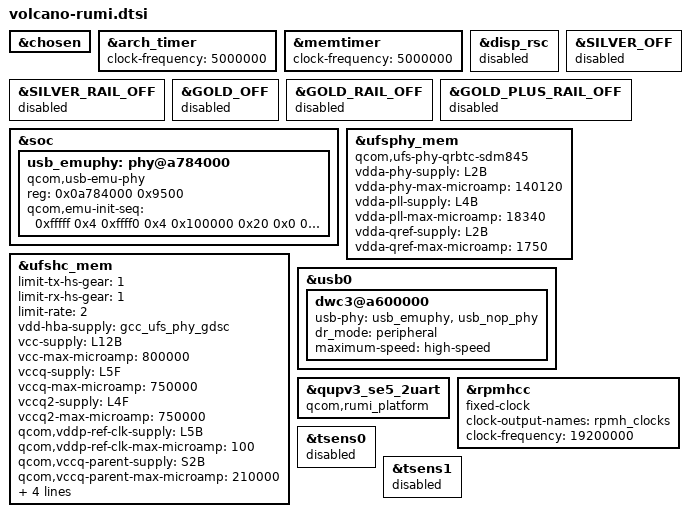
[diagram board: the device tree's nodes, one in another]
&chosen {
};

&arch_timer {
	clock-frequency = <5000000>;
};

&memtimer {
	clock-frequency = <5000000>;
};

&disp_rsc {
	status = "disabled";
};

&SILVER_OFF {
	status = "nok";
};

&SILVER_RAIL_OFF {
	status = "nok";
};

&GOLD_OFF {
	status = "nok";
};

&GOLD_RAIL_OFF {
	status = "nok";
};

&GOLD_PLUS_RAIL_OFF {
	status = "nok";
};

&soc {
	usb_emuphy: phy@a784000 {
		compatible = "qcom,usb-emu-phy";
		reg = <0x0a784000 0x9500>;

		qcom,emu-init-seq = <0xfffff 0x4
			0xffff0 0x4
			0x100000 0x20
			0x0 0x20
			0x000101F0 0x20
			0x00100000 0x3c
			0x0 0x3c
			0x0 0x4>;
	};
};

&ufsphy_mem {
	compatible = "qcom,ufs-phy-qrbtc-sdm845";

	/* VDDA_UFS_CORE */
	vdda-phy-supply = <&L2B>;
	vdda-phy-max-microamp = <140120>;

	/* VDDA_UFS_0_1P2 */
	vdda-pll-supply = <&L4B>;
	vdda-pll-max-microamp = <18340>;

	/* Qref power supply, Refer Qref diagram */
	vdda-qref-supply = <&L2B>;
	vdda-qref-max-microamp = <1750>;

	status = "ok";
};

&ufshc_mem {
	limit-tx-hs-gear = <1>;
	limit-rx-hs-gear = <1>;
	limit-rate = <2>; /* HS Rate-B */

	vdd-hba-supply = <&gcc_ufs_phy_gdsc>;

	vcc-supply = <&L12B>;
	vcc-max-microamp = <800000>;

	vccq-supply = <&L5F>;
	vccq-max-microamp = <750000>;

	vccq2-supply = <&L4F>;
	vccq2-max-microamp = <750000>;

	/* VDD_PX10 is voted for the ufs_reset_n */
	qcom,vddp-ref-clk-supply = <&L5B>;
	qcom,vddp-ref-clk-max-microamp = <100>;

	qcom,vccq-parent-supply = <&S2B>;
	qcom,vccq-parent-max-microamp = <210000>;

	qcom,disable-lpm;
	rpm-level = <0>;
	spm-level = <0>;

	qcom,iommu-dma = "bypass";

	status = "ok";
};

&usb0 {
	dwc3@a600000 {
		usb-phy = <&usb_emuphy>, <&usb_nop_phy>;
		dr_mode = "peripheral";
		maximum-speed = "high-speed";
	};
};

&qupv3_se5_2uart {
	qcom,rumi_platform;
};

&rpmhcc {
	compatible = "fixed-clock";
	clock-output-names = "rpmh_clocks";
	clock-frequency = <19200000>;
};

&tsens0 {
	status = "disabled";
};

&tsens1 {
	status = "disabled";
};
